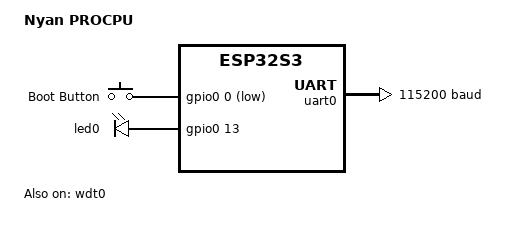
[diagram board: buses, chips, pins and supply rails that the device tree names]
/dts-v1/;

#include "espressif/esp32s3/esp32s3_wroom_n8.dtsi"
#include "nyan-pinctrl.dtsi"
#include <zephyr/dt-bindings/input/input-event-codes.h>
#include <espressif/partitions_0x0_amp.dtsi>

/ {
    model = "Nyan PROCPU";
    compatible = "espressif,esp32s3";

    aliases {
        watchdog0 = &wdt0;
        led-0 = &led0;
        uart-0 = &uart0;
        sw0 = &button0;
    };

    chosen {
        zephyr,sram = &sram0;
        zephyr,console = &uart0;
        zephyr,shell-uart = &uart0;
        zephyr,flash = &flash0;
        zephyr,code-partition = &slot0_partition;
    };

    buttons {
        compatible = "gpio-keys";
        button0: button_0 {
            gpios = <&gpio0 0 (GPIO_PULL_UP | GPIO_ACTIVE_LOW)>;
            label = "Boot Button";
            zephyr,code = <INPUT_KEY_0>;
        };
    };

    led {
        compatible = "gpio-leds";
        led0: d13 {
            gpios = <&gpio0 13 GPIO_ACTIVE_HIGH>;
        };
    };
};

&uart0 {
    status = "okay";
    current-speed = <115200>;
    pinctrl-0 = <&uart0_default>;
    pinctrl-names = "default";
};

&gpio0 {
    status = "okay";
};

&wdt0 {
    status = "okay";
};
